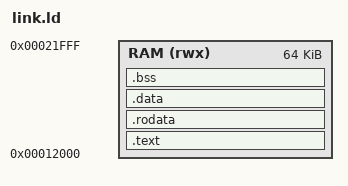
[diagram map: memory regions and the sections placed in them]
MEMORY {
	RAM  (rwx): ORIGIN = 0x12000, LENGTH = 64k
}

ENTRY(_start)

SECTIONS {
	.text : {
		*(.text.startup)
		*(.text)
		*(.text.*)
	} >RAM

	.rodata : {
		*(.rodata)
		*(.rodata.*)
	} >RAM

	.data : {
		*(.data)
		*(.data.*)
	} >RAM

	.bss : {
		_sbss = .;
		*(.bss)
		*(.bss.*)
		*(COMMON)
		_ebss = .;
	} >RAM

	end = .;
}
